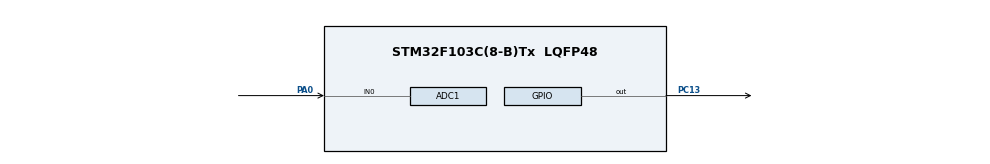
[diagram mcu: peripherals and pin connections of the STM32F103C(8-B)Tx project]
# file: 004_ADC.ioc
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ADC1.Channel-0\#ChannelRegularConversion=ADC_CHANNEL_0
ADC1.NbrOfConversionFlag=1
ADC1.Rank-0\#ChannelRegularConversion=1
ADC1.SamplingTime-0\#ChannelRegularConversion=ADC_SAMPLETIME_1CYCLE_5
ADC1.master=1
Mcu.Family=STM32F1
Mcu.Name=STM32F103C(8-B)Tx
Mcu.Package=LQFP48
NVIC.PriorityGroup=NVIC_PRIORITYGROUP_4
PA0-WKUP.Signal=ADCx_IN0
PA13.Mode=Serial_Wire
PA13.Signal=SYS_JTMS-SWDIO
PA14.Mode=Serial_Wire
PA14.Signal=SYS_JTCK-SWCLK
PC13-TAMPER-RTC.Signal=GPIO_Output
ProjectManager.HeapSize=0x200
ProjectManager.StackSize=0x400
ProjectManager.TargetToolchain=MDK-ARM V5.27
RCC.APB1Freq_Value=8000000
RCC.APB2Freq_Value=8000000
SH.ADCx_IN0.0=ADC1_IN0,IN0
board=custom

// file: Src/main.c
/* USER CODE BEGIN Header */
/**
  ******************************************************************************
  * @file           : main.c
  * @brief          : Main program body
  ******************************************************************************
  * @attention
  *
  * <h2><center>&copy; Copyright (c) 2023 STMicroelectronics.
  * All rights reserved.</center></h2>
  *
  * This software component is licensed by ST under BSD 3-Clause license,
  * the "License"; You may not use this file except in compliance with the
  * License. You may obtain a copy of the License at:
  *                        opensource.org/licenses/BSD-3-Clause
  *
  ******************************************************************************
  */
/* USER CODE END Header */

#include "main.h"

/* USER CODE BEGIN PD */
#define ADC_THRESHOLD 2000

/* USER CODE END PD */

/* USER CODE BEGIN PV */
uint16_t volatile adc_data;

/* USER CODE END PV */

void SystemClock_Config(void);
static void MX_GPIO_Init(void);
static void MX_ADC1_Init(void);

int main(void)
{

  /* MCU Configuration--------------------------------------------------------*/

  /* Reset of all peripherals, Initializes the Flash interface and the Systick. */

  LL_APB2_GRP1_EnableClock(LL_APB2_GRP1_PERIPH_AFIO);
  LL_APB1_GRP1_EnableClock(LL_APB1_GRP1_PERIPH_PWR);

  NVIC_SetPriorityGrouping(NVIC_PRIORITYGROUP_4);

  /* System interrupt init*/

  /** NOJTAG: JTAG-DP Disabled and SW-DP Enabled
  */
  LL_GPIO_AF_Remap_SWJ_NOJTAG();

  /* Configure the system clock */
  SystemClock_Config();

  /* Initialize all configured peripherals */
  MX_GPIO_Init();
  MX_ADC1_Init();
  /* USER CODE BEGIN 2 */
   LL_ADC_StartCalibration(ADC1);
	 while(!LL_ADC_IsCalibrationOnGoing(ADC1)){};
	 LL_ADC_Enable(ADC1);
		LL_ADC_REG_StartConversionSWStart(ADC1);

  /* USER CODE END 2 */

  /* Infinite loop */
  /* USER CODE BEGIN WHILE */
  while (1)
  {
		LL_mDelay(100);
	 adc_data = LL_ADC_REG_ReadConversionData12(ADC1);

    	while(!LL_ADC_IsActiveFlag_EOS(ADC1)){};
		  if (adc_data < ADC_THRESHOLD) LL_GPIO_ResetOutputPin(GPIOC, LL_GPIO_PIN_13);
		   else LL_GPIO_SetOutputPin(GPIOC, LL_GPIO_PIN_13);
    /* USER CODE END WHILE */

  }
}

void SystemClock_Config(void)
{
  LL_FLASH_SetLatency(LL_FLASH_LATENCY_0);

  if(LL_FLASH_GetLatency() != LL_FLASH_LATENCY_0)
  {
    Error_Handler();
  }
  LL_RCC_HSI_SetCalibTrimming(16);
  LL_RCC_HSI_Enable();

   /* Wait till HSI is ready */
  while(LL_RCC_HSI_IsReady() != 1)
  {

  }
  LL_RCC_SetAHBPrescaler(LL_RCC_SYSCLK_DIV_1);
  LL_RCC_SetAPB1Prescaler(LL_RCC_APB1_DIV_1);
  LL_RCC_SetAPB2Prescaler(LL_RCC_APB2_DIV_1);
  LL_RCC_SetSysClkSource(LL_RCC_SYS_CLKSOURCE_HSI);

   /* Wait till System clock is ready */
  while(LL_RCC_GetSysClkSource() != LL_RCC_SYS_CLKSOURCE_STATUS_HSI)
  {

  }
  LL_Init1msTick(8000000);
  LL_SetSystemCoreClock(8000000);
  LL_RCC_SetADCClockSource(LL_RCC_ADC_CLKSRC_PCLK2_DIV_2);
}

static void MX_ADC1_Init(void)
{

  LL_ADC_InitTypeDef ADC_InitStruct = {0};
  LL_ADC_CommonInitTypeDef ADC_CommonInitStruct = {0};
  LL_ADC_REG_InitTypeDef ADC_REG_InitStruct = {0};

  LL_GPIO_InitTypeDef GPIO_InitStruct = {0};

  /* Peripheral clock enable */
  LL_APB2_GRP1_EnableClock(LL_APB2_GRP1_PERIPH_ADC1);

  LL_APB2_GRP1_EnableClock(LL_APB2_GRP1_PERIPH_GPIOA);
  /**ADC1 GPIO Configuration
  PA0-WKUP   ------> ADC1_IN0
  */
  GPIO_InitStruct.Pin = LL_GPIO_PIN_0;
  GPIO_InitStruct.Mode = LL_GPIO_MODE_ANALOG;
  LL_GPIO_Init(GPIOA, &GPIO_InitStruct);

  /** Common config
  */
  ADC_InitStruct.DataAlignment = LL_ADC_DATA_ALIGN_RIGHT;
  ADC_InitStruct.SequencersScanMode = LL_ADC_SEQ_SCAN_DISABLE;
  LL_ADC_Init(ADC1, &ADC_InitStruct);
  ADC_CommonInitStruct.Multimode = LL_ADC_MULTI_INDEPENDENT;
  LL_ADC_CommonInit(__LL_ADC_COMMON_INSTANCE(ADC1), &ADC_CommonInitStruct);
  ADC_REG_InitStruct.TriggerSource = LL_ADC_REG_TRIG_SOFTWARE;
  ADC_REG_InitStruct.SequencerLength = LL_ADC_REG_SEQ_SCAN_DISABLE;
  ADC_REG_InitStruct.SequencerDiscont = LL_ADC_REG_SEQ_DISCONT_DISABLE;
  ADC_REG_InitStruct.ContinuousMode = LL_ADC_REG_CONV_CONTINUOUS;
  ADC_REG_InitStruct.DMATransfer = LL_ADC_REG_DMA_TRANSFER_NONE;
  LL_ADC_REG_Init(ADC1, &ADC_REG_InitStruct);
  /** Configure Regular Channel
  */
  LL_ADC_REG_SetSequencerRanks(ADC1, LL_ADC_REG_RANK_1, LL_ADC_CHANNEL_0);
  LL_ADC_SetChannelSamplingTime(ADC1, LL_ADC_CHANNEL_0, LL_ADC_SAMPLINGTIME_1CYCLE_5);

}

static void MX_GPIO_Init(void)
{
  LL_GPIO_InitTypeDef GPIO_InitStruct = {0};

  /* GPIO Ports Clock Enable */
  LL_APB2_GRP1_EnableClock(LL_APB2_GRP1_PERIPH_GPIOC);
  LL_APB2_GRP1_EnableClock(LL_APB2_GRP1_PERIPH_GPIOA);

  /**/
  LL_GPIO_ResetOutputPin(GPIOC, LL_GPIO_PIN_13);

  /**/
  GPIO_InitStruct.Pin = LL_GPIO_PIN_13;
  GPIO_InitStruct.Mode = LL_GPIO_MODE_OUTPUT;
  GPIO_InitStruct.Speed = LL_GPIO_SPEED_FREQ_LOW;
  GPIO_InitStruct.OutputType = LL_GPIO_OUTPUT_PUSHPULL;
  LL_GPIO_Init(GPIOC, &GPIO_InitStruct);

}

void Error_Handler(void)
{
}

/************************ (C) COPYRIGHT STMicroelectronics *****END OF FILE****/
